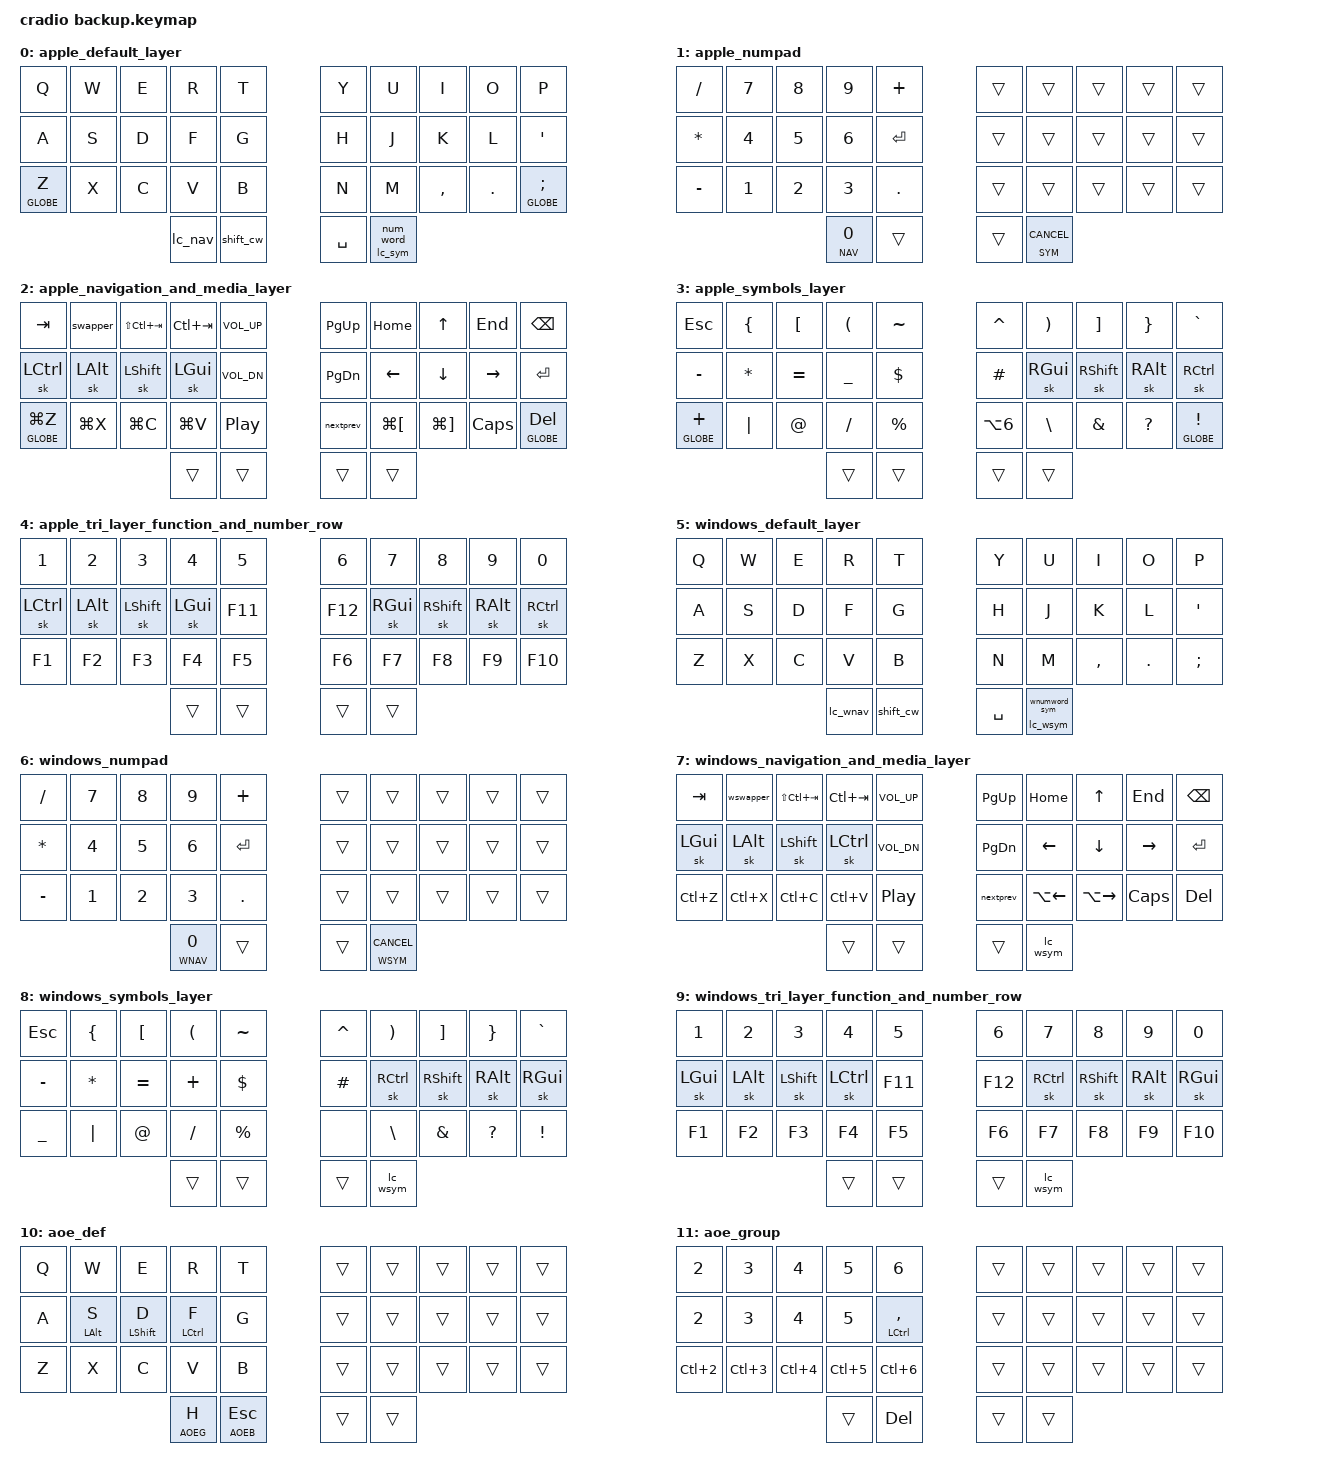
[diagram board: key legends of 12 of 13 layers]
#include <behaviors.dtsi>
#include <dt-bindings/zmk/bt.h>
#include <dt-bindings/zmk/keys.h>
// #include "apple_globe.h" // This has been merged to main ZMK, so it can be droped after I rebase my own fork

// Apple layers (CASG mods)
#define DEF 0
#define NUM 1
#define NAV 2
#define SYM 3
#define FUN 4

// Windows layers (GASC mods)
#define WDEF 5
#define WNUM 6
#define WNAV 7
#define WSYM 8
#define WFUN 9

// AOE Layers
#define AOED 10
#define AOEG 11
#define AOEB 12

&caps_word {
    continue-list = <UNDERSCORE MINUS SQT CARET TILDE GRAVE K_CANCEL BACKSPACE DELETE LSHFT>;
    /delete-property/ ignore-modifiers;
};

&mt {
    flavor = "tap-preferred";
};

&sk {
     release-after-ms = <600000>; // set to a bonkers 10mins default is 1s 1000ms
     quick-release;
};

/ {
    combos {
        compatible = "zmk,combos";

        // macOS combos
        combo_toggle_nav {
            key-positions = <30 31>;
            layers = <DEF NAV>;
            bindings = <&tog NAV>;
        };
        combo_expose {
            key-positions = <2 3>;
            layers = <NAV>;
            bindings = <&expose>;
        };
        combo_hyper {
            key-positions = <32 33>;
            layers = <DEF>;
            bindings = <&kp LS(LC(LA(LCMD)))>;
        };

        // Windows combos

        combo_toggle_between_windows_and_apple_mods {
            key-positions = <10 19>; // A "
            layers = <FUN WFUN>;
            bindings = <&tog WNAV>;
        };

        combo_toggle_wnav {
            key-positions = <30 31>;
            layers = <WDEF WNAV>;
            bindings = <&tog WNAV>;
        };

        // Multimedia and keyboard features (OS agnostic)

        combo_mute {
            key-positions = <4 14>; // Vol up + down keys
            layers = <NAV WNAV>;
            bindings = <&kp C_MUTE>;
        };

        combo_trigger_bootloader {
            key-positions = <20 21>;
            layers = <FUN WFUN>;
            bindings = <&bootloader>;
        };

        // Bluetooth toggles

        combo_toggle_bt0_connection {
            key-positions = <3 4>;
            layers = <FUN WFUN>;
            bindings = <&bt BT_SEL 0>;
        };

        combo_toggle_bt1_connection {
            key-positions = <13 14>;
            layers = <FUN WFUN>;
            bindings = <&bt BT_SEL 1>;
        };

        combo_toggle_bt2_connection {
            key-positions = <23 24>;
            layers = <FUN WFUN>;
            bindings = <&bt BT_SEL 2>;
        };

        combo_clear_current_bluetooth_profile {
            key-positions = <28 29>;
            layers = <FUN WFUN>;
            bindings = <&bt BT_CLR>;
        };

        // AOE layers

        combo_toggle_aoe {
            bindings = <&tog AOED>;
            key-positions = <1 2 3>;
            layers = <DEF WDEF AOED>;
        };

        aoe_pause {
            bindings = <&kp F3>;
            key-positions = <21 22 23>;
            layers = <AOED>;
        };
    };

    behaviors {
        
        // Tap dances
        
        shift_cw: tap_dance_shift_and_caps_word {
            compatible = "zmk,behavior-tap-dance";
            label = "TAP_DANCE_SHIFT_CAPS_WORD";
            #binding-cells = <0>;
            tapping-term-ms = <300>;
            bindings =
                <&kp RSHFT>,
                <&caps_word>;
        };

        nextprev: nextprev {
            compatible = "zmk,behavior-tap-dance";
            label = "NEXT-PREVIOUS";
            #binding-cells = <0>;
            tapping-term-ms = <250>;
            bindings =
                <&kp C_NEXT>,
                <&kp C_PREVIOUS>;
        };
        expose: expose_tap_dance {
            compatible = "zmk,behavior-tap-dance";
            label = "EXPOSE_TAP_DANCE";
            #binding-cells = <0>;
            tapping-term-ms = <250>;
            bindings =
                <&kp C_AC_DESKTOP_SHOW_ALL_WINDOWS>,
                <&kp LG(C_AC_DESKTOP_SHOW_ALL_WINDOWS)>;
                
        };

        // Swappers

        swapper: swapper {
            compatible = "zmk,behavior-tri-state"; // requires tri-state PR #1366 (not yet merged into main)
            label = "SWAPPER";
            #binding-cells = <0>;
            bindings =
                <&kt LCMD>,
                <&kp TAB>,
                <&kt LCMD>;

            ignored-key-positions = <0 3 7 9 16 17 18 28 29>; // Tab, Shift, Arrow key positions and DEL/BSPC to quit app/close window from altTab
        };

        wswapper: windows_swapper {
            compatible = "zmk,behavior-tri-state"; // requires tri-state PR #1366 (not yet merged into main)
            label = "WINDOWS_SWAPPER";
            #binding-cells = <0>;
            bindings =
                <&kt LALT>,
                <&kp TAB>,
                <&kt LALT>;

            ignored-key-positions = <3>; // Shift key on WNAV to allow for backwards movement
        };

        // num_word for macOS and Windows

        num_word: behavior_num_word {
            compatible = "zmk,behavior-caps-word"; // Custom caps-word behavior form PR #1451
            label = "NUM_WORD";
            #binding-cells = <0>;
            layers = <NUM>; // insert location of numbers layer here
            continue-list = <BACKSPACE DELETE DOT COMMA SEMI COLON SLASH PLUS MINUS ASTRK EQUAL>; // adjust as desired
            ignore-numbers; // numbers don't deactivate the layer
            ignore-modifiers; // mods don't deactivate the layer
        };

        wnum_word: win_behavior_num_word {
            compatible = "zmk,behavior-caps-word"; // Custom caps-word behavior form PR #1451
            label = "WINDOWS_NUM_WORD";
            #binding-cells = <0>;
            layers = <WNUM>; // insert location of numbers layer here
            continue-list = <BACKSPACE DELETE DOT COMMA SEMI COLON SLASH PLUS MINUS ASTRK EQUAL>; // adjust as desired
            ignore-numbers; // numbers don't deactivate the layer
            ignore-modifiers; // mods don't deactivate the layer
        };

        numword_sym: numword_sym { // combines. tap: &num_word, hold: SYM (with cancel)
            compatible = "zmk,behavior-hold-tap";
            label = "NUMWORD_SYM";
            bindings =
                <&lc_sym>,
                <&num_word>;
            #binding-cells = <2>;
            tapping-term-ms = <200>;
        };
        
        wnumword_sym: win_numword_sym { // for the keymap on windows layers. tap: &wnum_word, hold: WSYM (with cancel)
            compatible = "zmk,behavior-hold-tap";
            label = "WINDOWS_NUMWORD_SYM";
            bindings =
                <&lc_wsym>,
                <&wnumword_sym>;
            #binding-cells = <2>;
            tapping-term-ms = <200>;
        };
        
        hp_mt: hp_mt { // hold-preffered mod taps
            compatible = "zmk,behavior-hold-tap";
            label = "HOLD_PREFFERED_MOD_TAP";
            flavor = "hold-preferred";
            bindings =
                <&kp>,
                <&kp>;
            #binding-cells = <2>;
            tapping-term-ms = <200>;
        };
    };

    macros {
        lc_nav: lc_nav {
            label = "LC_NAV";
            compatible = "zmk,behavior-macro";
            wait-ms = <0>;
            tap-ms = <0>;
            #binding-cells = <0>;
            bindings =
                <&macro_press>,
                <&mo NAV>,
                <&macro_tap>,
                <&kp K_CANCEL>,
                <&macro_pause_for_release>,
                <&macro_release>,
                <&mo NAV>;
        };
        lc_sym: lc_sym {
            label = "LC_SYM";
            compatible = "zmk,behavior-macro";
            wait-ms = <0>;
            tap-ms = <0>;
            #binding-cells = <0>;
            bindings =
                <&macro_press>,
                <&mo SYM>,
                <&macro_tap>,
                <&kp K_CANCEL>,
                <&macro_pause_for_release>,
                <&macro_release>,
                <&mo SYM>;
        };
        lc_wnav: lc_wnav {
            label = "LC_WNAV";
            compatible = "zmk,behavior-macro";
            wait-ms = <0>;
            tap-ms = <0>;
            #binding-cells = <0>;
            bindings =
                <&macro_press>,
                <&mo WNAV>,
                <&macro_tap>,
                <&kp K_CANCEL>,
                <&macro_pause_for_release>,
                <&macro_release>,
                <&mo WNAV>;
        };
        lc_wsym: lc_wsym {
            label = "LC_WSYM";
            compatible = "zmk,behavior-macro";
            wait-ms = <0>;
            tap-ms = <0>;
            #binding-cells = <0>;
            bindings =
                <&macro_press>,
                <&mo WSYM>,
                <&macro_tap>,
                <&kp K_CANCEL>,
                <&macro_pause_for_release>,
                <&macro_release>,
                <&mo WSYM>;
        };
    };

    conditional_layers {
        compatible = "zmk,conditional-layers";

        macos_tri_layer {
            if-layers = <NAV SYM>;
            then-layer = <FUN>;
        };

        windows_tri_layer {
            if-layers = <WNAV WSYM>;
            then-layer = <WFUN>;
        };
    };

    keymap {
        compatible = "zmk,keymap";

        apple_default_layer {
            bindings = <
                &kp Q        &kp W  &kp E  &kp R    &kp T          &kp Y      &kp U   &kp I      &kp O    &kp P
                &kp A        &kp S  &kp D  &kp F    &kp G          &kp H      &kp J   &kp K      &kp L    &kp SQT
                &mt GLOBE Z  &kp X  &kp C  &kp V    &kp B          &kp N      &kp M   &kp COMMA  &kp DOT  &mt GLOBE SEMI
                                           &lc_nav  &shift_cw      &kp SPACE  &numword_sym 0 0
            >;
        };

        apple_numpad {
            bindings = <
                &kp SLASH  &kp N7  &kp N8  &kp N9      &kp PLUS   &trans  &trans  &trans  &trans  &trans
                &kp ASTRK  &kp N4  &kp N5  &kp N6      &kp ENTER  &trans  &trans  &trans  &trans  &trans
                &kp MINUS  &kp N1  &kp N2  &kp N3      &kp DOT    &trans  &trans  &trans  &trans  &trans
                                           &lt NAV N0  &trans     &trans  &lt SYM K_CANCEL
            >;
        };

        apple_navigation_and_media_layer {
            bindings = <
                &kp TAB          &swapper   &kp LS(LC(TAB))  &kp LC(TAB)  &kp C_VOL_UP       &kp PG_UP  &kp HOME      &kp UP        &kp END    &kp BSPC
                &sk LCTRL        &sk LALT   &sk LSHFT        &sk LGUI     &kp C_VOL_DN       &kp PG_DN  &kp LEFT      &kp DOWN      &kp RIGHT  &kp ENTER
                &mt GLOBE LG(Z)  &kp LG(X)  &kp LG(C)        &kp LG(V)    &kp C_PLAY_PAUSE   &nextprev   &kp LG(LBKT)  &kp LG(RBKT)  &kp CAPS   &mt GLOBE DEL
                                                             &trans       &trans             &trans     &trans
            >;
        };

        apple_symbols_layer {
            bindings = <
                &kp ESC          &kp LBRC   &kp LBKT   &kp LPAR   &kp TILDE    &kp CARET   &kp RPAR  &kp RBKT   &kp RBRC   &kp GRAVE
                &kp MINUS        &kp ASTRK  &kp EQUAL  &kp UNDER  &kp DLLR     &kp HASH    &sk RGUI  &sk RSHFT  &sk RALT   &sk RCTRL
                &mt GLOBE PLUS   &kp PIPE   &kp AT     &kp FSLH   &kp PRCNT    &kp LA(N6)  &kp BSLH  &kp AMPS   &kp QMARK  &mt GLOBE EXCL
                                                       &trans     &trans       &trans      &trans
            >;
        };

        apple_tri_layer_function_and_number_row {
            bindings = <
                &kp N1     &kp N2    &kp N3     &kp N4    &kp N5     &kp N6   &kp N7    &kp N8     &kp N9    &kp N0
                &sk LCTRL  &sk LALT  &sk LSHFT  &sk LGUI  &kp F11    &kp F12  &sk RGUI  &sk RSHFT  &sk RALT  &sk RCTRL
                &kp F1     &kp F2    &kp F3     &kp F4    &kp F5     &kp F6   &kp F7    &kp F8     &kp F9    &kp F10
                                                &trans    &trans     &trans   &trans
            >;
        };

        windows_default_layer {
            bindings = <
                &kp Q  &kp W  &kp E  &kp R     &kp T        &kp Y    &kp U     &kp I      &kp O    &kp P
                &kp A  &kp S  &kp D  &kp F     &kp G        &kp H    &kp J     &kp K      &kp L    &kp SQT
                &kp Z  &kp X  &kp C  &kp V     &kp B        &kp N    &kp M     &kp COMMA  &kp DOT  &kp SEMI
                                     &lc_wnav  &shift_cw    &kp SPC  &wnumword_sym 0 0
            >;
        };

        windows_numpad {
            bindings = <
                &kp SLASH  &kp N7  &kp N8  &kp N9      &kp PLUS    &trans  &trans  &trans  &trans  &trans
                &kp ASTRK  &kp N4  &kp N5  &kp N6      &kp ENTER   &trans  &trans  &trans  &trans  &trans
                &kp MINUS  &kp N1  &kp N2  &kp N3      &kp DOT     &trans  &trans  &trans  &trans  &trans
                                           &lt WNAV N0 &trans      &trans  &lt WSYM K_CANCEL
            >;
        };

        windows_navigation_and_media_layer {
            bindings = <
                &kp TAB    &wswapper  &kp LS(LC(TAB))  &kp LC(TAB)  &kp C_VOL_UP       &kp PG_UP  &kp HOME      &kp UP         &kp END    &kp BSPC
                &sk LGUI   &sk LALT   &sk LSHFT        &sk LCTRL    &kp C_VOL_DN       &kp PG_DN  &kp LEFT      &kp DOWN       &kp RIGHT  &kp ENTER
                &kp LC(Z)  &kp LC(X)  &kp LC(C)        &kp LC(V)    &kp C_PLAY_PAUSE   &nextprev   &kp LA(LEFT)  &kp LA(RIGHT)  &kp CAPS   &kp DEL
                                                       &trans       &trans             &trans     &lc_wsym
            >;
        };

        windows_symbols_layer {
            bindings = <
                &kp ESC    &kp LBRC   &kp LBKT   &kp LPAR  &kp TILDE    &kp CARET  &kp RPAR   &kp RBKT   &kp RBRC   &kp GRAVE
                &kp MINUS  &kp ASTRK  &kp EQUAL  &kp PLUS  &kp DLLR     &kp HASH   &sk RCTRL  &sk RSHFT  &sk RALT   &sk RGUI
                &kp UNDER  &kp PIPE   &kp AT     &kp FSLH  &kp PRCNT    &none      &kp BSLH   &kp AMPS   &kp QMARK  &kp EXCL
                                                 &trans    &trans       &trans     &lc_wsym
            >;
        };

        windows_tri_layer_function_and_number_row {
            bindings = <
                &kp N1    &kp N2    &kp N3     &kp N4     &kp N5     &kp N6   &kp N7     &kp N8     &kp N9    &kp N0
                &sk LGUI  &sk LALT  &sk LSHFT  &sk LCTRL  &kp F11    &kp F12  &sk RCTRL  &sk RSHFT  &sk RALT  &sk RGUI
                &kp F1    &kp F2    &kp F3     &kp F4     &kp F5     &kp F6   &kp F7     &kp F8     &kp F9    &kp F10
                                               &trans     &trans     &trans   &lc_wsym
            >;
        };

        aoe_def {
            bindings = <
                &kp Q  &kp W       &kp E        &kp R        &kp T         &trans  &trans  &trans  &trans  &trans
                &kp A  &mt LALT S  &mt LSHFT D  &mt LCTRL F  &kp G         &trans  &trans  &trans  &trans  &trans
                &kp Z  &kp X       &kp C        &kp V        &kp B         &trans  &trans  &trans  &trans  &trans
                                                &lt AOEG H   &lt AOEB ESC  &trans  &trans
            >;
        };

        aoe_group {
            bindings = <
                &kp N2      &kp N3      &kp N4      &kp N5      &kp N6             &trans  &trans  &trans  &trans  &trans
                &kp N2      &kp N3      &kp N4      &kp N5      &mt LCTRL COMMA    &trans  &trans  &trans  &trans  &trans
                &kp LC(N2)  &kp LC(N3)  &kp LC(N4)  &kp LC(N5)  &kp LC(N6)         &trans  &trans  &trans  &trans  &trans
                                                    &trans      &kp DEL            &trans  &trans
            >;
        };

        aoe_buildings {
            bindings = <
                &kp LC(LS(M))  &kp LC(LS(S))  &kp LC(LS(U))  &kp LC(LS(Y))  &kp LC(LS(D))    &trans  &trans  &trans  &trans  &trans
                &kp LC(LS(A))  &kp LC(LS(L))  &kp LC(LS(B))  &kp LC(LS(K))  &kp LS(DOT)      &trans  &trans  &trans  &trans  &trans
                &kp LC(LS(Z))  &kp LC(LS(I))  &kp LC(LS(G))  &kp LC(LS(V))  &kp LS(COMMA)    &trans  &trans  &trans  &trans  &trans
                                                             &kp LC(LS(H))  &trans           &trans  &trans
            >;
        };

    };
};
